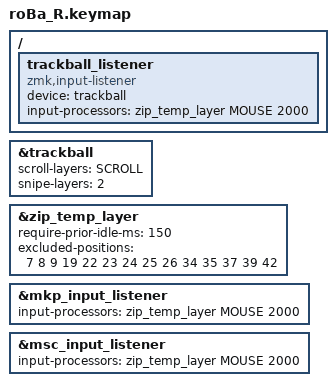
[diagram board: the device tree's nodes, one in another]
#include "roBa_L.keymap"
#include <input/processors.dtsi>

#include "boards/shields/Test/roBa_R.overlay"
&trackball {
    // automouse-layer はドライバ側で管理せず、zip_temp_layer 側に一本化する。
    // （ドライバの k_timer が切れると延長中でも MOUSE レイヤーを消してしまい、
    //   クリック/スクロールでのタイムアウト延長と併存できないため）
    // automouse-layer = <MOUSE>;
    scroll-layers = <SCROLL>;
    snipe-layers = <2>;

    // arrows {
    //     layers = <2>;
    //     bindings =
    //         <&kp RIGHT_ARROW>,
    //         <&kp LEFT_ARROW>,
    //         <&kp UP_ARROW>,
    //         <&kp DOWN_ARROW>;

    //     tick = <5>;
    //     wait-ms = <5>;
    //     tap-ms = <5>;
    // };

};

// オートマウスレイヤー(MOUSE)の誤爆対策。
// require-prior-idle-ms: 直前 150ms 以内にキー入力があれば、トラボ移動でも MOUSE を発動させない（タイピング中の誤爆防止の本命）。
// excluded-positions: AML 中でも下記の位置のキーは MOUSE を抜けない（クリック/スクロール継続用）。
//   それ以外のキーを押すと押した瞬間に MOUSE を抜ける（通常の &kp/&mt のまま通るのでホールド/長押しリピートは壊れない）。
//   7=I(MB1) 8=O(scroll) 9=P(MB2) 19=K(MB1) 42=右親指(MB1)
//   22=Z 23=X 24=C 25=V 26=B … Ctrl+Z/X/C/V コンボ用。トラボ範囲選択→コピー/カット後も AML を維持する。
//     (コンボの両キー位置が除外でないと、押下で MOUSE レイヤーが抜けてしまうため両方を除外)
//   34=LCTRL 35=LWIN 37=LALT 39=LSHIFT … 最下段モディファイア。Shift+クリック等のため AML を維持する。
//   ※ I/O/P を打って誤爆するのが気になる場合は 7 と 9 をリストから外すと、それらも押下で即解除になる。
&zip_temp_layer {
    require-prior-idle-ms = <150>;
    excluded-positions = <7 8 9 19 22 23 24 25 26 34 35 37 39 42>;
};

// 物理トラックボールの移動・スクロールで MOUSE レイヤーを2秒延長する。
// ※ overlay 側に置くと、シールド機構が overlay を単体コンパイルする経路で
//    MOUSE マクロ(roBa_L.keymap の #define)が未定義になりビルドが落ちる。
//    MOUSE と zip_temp_layer が両方使える keymap 側で定義する。
/ {
    trackball_listener {
        compatible = "zmk,input-listener";
        device = <&trackball>;
        input-processors = <&zip_temp_layer MOUSE 2000>;
    };
};

// クリック・右クリック・スクロールでも MOUSE レイヤーのタイムアウトを延長する。
&mkp_input_listener {
    input-processors = <&zip_temp_layer MOUSE 2000>;
};

&msc_input_listener {
    input-processors = <&zip_temp_layer MOUSE 2000>;
};
